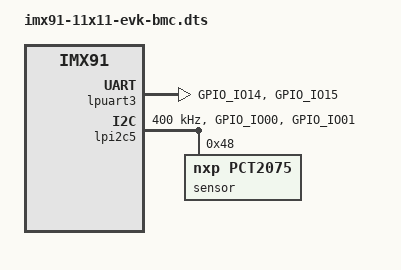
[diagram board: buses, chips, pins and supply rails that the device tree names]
// SPDX-License-Identifier: (GPL-2.0+ OR MIT)
/*
 * Copyright 2025 NXP
 */

#include "imx91-11x11-evk.dts"

&lpuart3 {
	pinctrl-names = "default";
	pinctrl-0 = <&pinctrl_uart3>;
	status = "okay";
};

&lpi2c5 {
#address-cells = <1>;
#size-cells = <0>;
        clock-frequency = <400000>;
        pinctrl-names = "default", "sleep";
        pinctrl-0 = <&pinctrl_lpi2c5>;
        pinctrl-1 = <&pinctrl_lpi2c5>;
        status = "okay";

        sensor@48 {
                compatible = "nxp,pct2075";
                reg = <0x48>;
        };
};

&iomuxc {
/* uart test port2: J1001: Pin8--TX Pin10--RX */
	pinctrl_uart3: uart3grp {
		fsl,pins = <
			MX91_PAD_GPIO_IO14__LPUART3_TX		0x31e
			MX91_PAD_GPIO_IO15__LPUART3_RX		0x31e
		>;
	};

/* sensor port: J1001: Pin27--SDA Pin28-SCL */
        pinctrl_lpi2c5: lpi2c5grp {
                 fsl,pins = <
                          MX91_PAD_GPIO_IO00__LPI2C5_SDA        0x40000b9e
                          MX91_PAD_GPIO_IO01__LPI2C5_SCL        0x40000b9e
                 >;
        };
};
